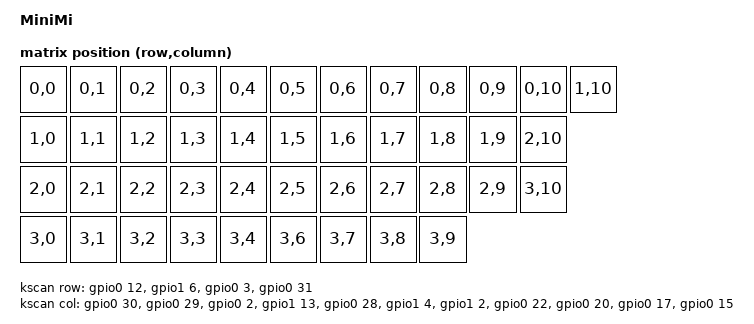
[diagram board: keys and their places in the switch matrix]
// This file was generated from a template. Edit it to match your keyboard.
// See https://docs.zephyrproject.org/4.1.0/hardware/porting/board_porting.html
// and https://zmk.dev/docs/development/hardware-integration/new-shield for more
// instructions.

/dts-v1/;
#include <nordic/nrf52840_qiaa.dtsi>
#include <dt-bindings/zmk/matrix_transform.h>
#include <dt-bindings/led/led.h>

#include "minimi-pinctrl.dtsi"
#include "minimi-layouts.dtsi"

/ {
    model = "MiniMi";
    compatible = "minimi";

    chosen {
        zephyr,code-partition = &code_partition;
        zephyr,sram = &sram0;
        zephyr,flash = &flash0;
        // Uncomment this if you enabled one of the "vddh" nodes below.
        zmk,battery = &vbatt;
        zmk,physical-layout = &default_layout;
        zmk,underglow = &led_strip;
    };

    kscan: kscan {
        // If the hardware does not use a switch matrix, change this to the
        // appropriate driver and update the properties below to match.
        // See https://zmk.dev/docs/config/kscan for supported key scan drivers.
        compatible = "zmk,kscan-gpio-matrix";
        // Set this to "col2row" or "row2col" to match the hardware. If using
        // "row2col", change the col-gpios to (GPIO_ACTIVE_HIGH | GPIO_PULL_DOWN)
        // and the row-gpios to GPIO_ACTIVE_HIGH.
        diode-direction = "col2row";
        wakeup-source;

        // Replace these comments with the GPIO pins in the matrix.
        // See https://zmk.dev/docs/development/hardware-integration/new-shield#shield-overlays
        col-gpios
            = <&gpio0 30 GPIO_ACTIVE_HIGH>
            , <&gpio0 29 GPIO_ACTIVE_HIGH>
            , <&gpio0 2 GPIO_ACTIVE_HIGH>
            , <&gpio1 13 GPIO_ACTIVE_HIGH>
            , <&gpio0 28 GPIO_ACTIVE_HIGH>
            , <&gpio1 4 GPIO_ACTIVE_HIGH>
            , <&gpio1 2 GPIO_ACTIVE_HIGH>
            , <&gpio0 22 GPIO_ACTIVE_HIGH>
            , <&gpio0 20 GPIO_ACTIVE_HIGH>
            , <&gpio0 17 GPIO_ACTIVE_HIGH>
            , <&gpio0 15 GPIO_ACTIVE_HIGH>
            ;

        row-gpios
            = <&gpio0 12 (GPIO_ACTIVE_HIGH | GPIO_PULL_DOWN)>
            , <&gpio1 6 (GPIO_ACTIVE_HIGH | GPIO_PULL_DOWN)>
            , <&gpio0 3 (GPIO_ACTIVE_HIGH | GPIO_PULL_DOWN)>
            , <&gpio0 31 (GPIO_ACTIVE_HIGH | GPIO_PULL_DOWN)>
            ;
    };

    default_transform: default_transform {
        // See https://zmk.dev/docs/development/hardware-integration/new-shield#matrix-transform
        // for how to configure this
        compatible = "zmk,matrix-transform";
        columns = <11>;
        rows = <4>;

        map = <
            RC(0, 0) RC(0, 1) RC(0, 2) RC(0, 3) RC(0, 4) RC(0, 5) RC(0, 6) RC(0, 7) RC(0, 8) RC(0, 9) RC(0, 10) RC(1, 10)
            RC(1, 0) RC(1, 1) RC(1, 2) RC(1, 3) RC(1, 4) RC(1, 5) RC(1, 6) RC(1, 7) RC(1, 8) RC(1, 9) RC(2, 10)
            RC(2, 0) RC(2, 1) RC(2, 2) RC(2, 3) RC(2, 4) RC(2, 5) RC(2, 6) RC(2, 7) RC(2, 8) RC(2, 9) RC(3, 10)
            RC(3, 0) RC(3, 1) RC(3, 2) RC(3, 3) RC(3, 4) RC(3, 6) RC(3, 7) RC(3, 8) RC(3, 9)
        >;
    };

    leds {
        compatible = "gpio-leds";

        // If you have a GPIO routed to a status LED, set it here.
        // Otherwise, delete this block.
        red_led: led_0 {
            gpios = <&gpio0 26 GPIO_ACTIVE_HIGH>;
        };
    };

    // If you are powering the SoC from the VDDH pin, uncomment this block.
    // Otherwise, delete it.

    // vbatt: vbatt {
    //     compatible = "zmk,battery-nrf-vddh";
    // };

    // If you are powering the SoC from the VDD pin and you have a voltage divider
    // routed to an analog pin to read the battery voltage, uncomment this block
    // and assign the correct ADC channel and resistance values.
    // Otherwise, delete it.

    vbatt: vbatt {
        compatible = "zmk,battery-voltage-divider";
        io-channels = <&adc 2>;
        output-ohms = <2000000>;
        full-ohms = <(2000000 + 820000)>;
    };
};

// Uncomment this to switch from the LDO to the DC/DC regulator on REG0.
// Do not enable the DC/DC regulator without an LC filter connected to the DCCH
// pin, or the keyboard will not boot until an LC filter is connected.
// &reg0 {
//     status = "okay";
// };

// Uncomment this to switch from the LDO to the DC/DC regulator on REG1.
// Do not enable the DC/DC regulator without an LC filter connected to the DCC
// pin, or the keyboard will not boot until an LC filter is connected.
// &reg1 {
//     regulator-initial-mode = <NRF5X_REG_MODE_DCDC>;
// };

&adc {
    status = "okay";
};

&gpiote {
    status = "okay";
};

&gpio0 {
    status = "okay";
};

&gpio1 {
    status = "okay";
};

&spi3 {
    compatible = "nordic,nrf-spim";
    status = "okay";

    pinctrl-0 = <&spi3_default>;
    pinctrl-1 = <&spi3_sleep>;
    pinctrl-names = "default", "sleep";

    led_strip: ws2812@0 {
        compatible = "worldsemi,ws2812-spi";

        /* SPI */
        reg = <0>; /* ignored, but necessary for SPI bindings */
        spi-max-frequency = <4000000>;

        /* WS2812 */
        chain-length = <4>; /* number of LEDs */
        spi-one-frame = <0x70>;
        spi-zero-frame = <0x40>;
        color-mapping = <LED_COLOR_ID_GREEN
                         LED_COLOR_ID_RED
                         LED_COLOR_ID_BLUE>;
    };
};

// If you use the NFC pins as GPIOs, uncomment this. Otherwise, remove it.
// &uicr {
//     nfct-pins-as-gpios;
// };

zephyr_udc0: &usbd {
    status = "okay";
};

&flash0 {
    // Adjust this flash map as is necessary for your board. For more information, see
    // https://docs.zephyrproject.org/4.1.0/services/storage/flash_map/flash_map.html#relationship-with-devicetree
    partitions {
        compatible = "fixed-partitions";
        #address-cells = <1>;
        #size-cells = <1>;

        code_partition: partition@1000 {
            reg = <DT_SIZE_K(4) DT_SIZE_K(844)>;
        };

        // If using a bootloader with SoftDevice included, replace the code_partition
        // node above with the following. If using SoftDevice v7, change 26000 to 27000.

        // sd_partition: partition@0 {
        //     reg = <0x0 <DT_SIZE_K(4)>;
        // };
        // code_partition: partition@26000 {
        //     reg = <DT_SIZE_K(152) DT_SIZE_K(792)>;
        // };

        // The flash starting at 0x000d4000 and ending at
        // 0x000f3fff is reserved for use by the application.

        // Storage partition will be used by NVS if enabled.
        storage_partition: partition@d4000 {
            reg = <DT_SIZE_K(848) DT_SIZE_K(128)>;
        };

        boot_partition: partition@f4000 {
            reg = <DT_SIZE_K(976) DT_SIZE_K(48)>;
        };
    };
};
